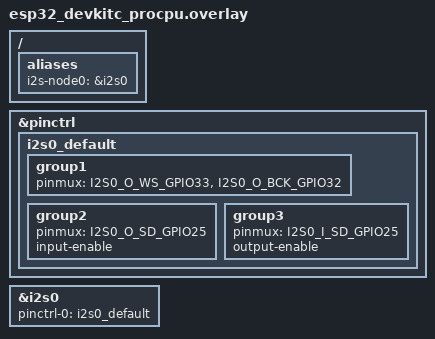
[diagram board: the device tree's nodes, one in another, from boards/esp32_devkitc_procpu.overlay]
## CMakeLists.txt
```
# SPDX-License-Identifier: Apache-2.0

cmake_minimum_required(VERSION 3.28.0)

find_package(Zephyr REQUIRED HINTS $ENV{ZEPHYR_BASE})
project(i2s_test)

FILE(GLOB app_sources src/*.c)
list(FILTER app_sources EXCLUDE REGEX "test_i2s_pm\\.c$")
target_sources(app PRIVATE ${app_sources})
target_sources_ifdef(CONFIG_PM app PRIVATE src/test_i2s_pm.c)
```

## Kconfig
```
#
# Copyright (c) 2025 Espressif Systems (Shanghai) CO LTD
#
# SPDX-License-Identifier: Apache-2.0
#

mainmenu "ESP32 I2S Loopback Test"

source "Kconfig.zephyr"

config I2S_TEST_SEPARATE_DEVICES
	bool "Use two separate I2S ports for loopback"
	help
	  Use separate I2S ports for transmit and receive.

config I2S_TEST_USE_GPIO_LOOPBACK
	bool "Use GPIO loopback"
	help
	  Use wiring between the data-out and data-in pins for looping back data.

config I2S_TEST_ALLOWED_DATA_DISCARD
	int "Allowed discard in received data"
	default 0
	help
	  Drop the first received block and allow later blocks to start this many
	  samples away from the transmitted block boundary. The offset must stay
	  fixed for the rest of the stream.
```

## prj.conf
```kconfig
CONFIG_I2S=y
CONFIG_ZTEST=y
CONFIG_TEST_USERSPACE=y
```

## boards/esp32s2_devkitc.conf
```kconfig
# Copyright (c) 2025 Espressif Systems (Shanghai) Co., Ltd.
# SPDX-License-Identifier: Apache-2.0

CONFIG_I2S_TEST_USE_GPIO_LOOPBACK=y
CONFIG_I2S_TEST_ALLOWED_DATA_DISCARD=2
CONFIG_I2S_ESP32_ALLOWED_EMPTY_TX_QUEUE_DEFERRAL_TIME_MS=1
```

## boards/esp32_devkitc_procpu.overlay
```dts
/*
 * Copyright (c) 2025 Espressif Systems (Shanghai) Co., Ltd.
 *
 * SPDX-License-Identifier: Apache-2.0
 */

/* i2s-node0 is the transmitter/receiver */

/ {
	aliases {
		i2s-node0 = &i2s0;
	};
};

&pinctrl {
	i2s0_default: i2s0_default {
		group1 {
			pinmux = <I2S0_O_WS_GPIO33>,
				 <I2S0_O_BCK_GPIO32>;
		};

		group2 {
			pinmux = <I2S0_O_SD_GPIO25>;
			input-enable;
		};

		group3 {
			pinmux = <I2S0_I_SD_GPIO25>;
			output-enable;
		};
	};
};

&i2s0 {
	pinctrl-0 = <&i2s0_default>;
	pinctrl-names = "default";
};
```

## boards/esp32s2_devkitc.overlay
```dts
/*
 * Copyright (c) 2025 Espressif Systems (Shanghai) Co., Ltd.
 *
 * SPDX-License-Identifier: Apache-2.0
 */

/* i2s-node0 is the transmitter/receiver */

/ {
	aliases {
		i2s-node0 = &i2s0;
	};
};

&i2s0_default {
	group1 {
		pinmux = <I2S0_O_WS_GPIO5>,
			 <I2S0_O_BCK_GPIO6>;
	};

	group2 {
		pinmux = <I2S0_O_SD_GPIO18>;
		input-enable;
	};

	group3 {
		pinmux = <I2S0_I_SD_GPIO18>;
		output-enable;
	};
};

&i2s0 {

	interrupts = <I2S0_INTR_SOURCE IRQ_DEFAULT_PRIORITY 0>,
		     <I2S0_INTR_SOURCE IRQ_DEFAULT_PRIORITY 0>;
	interrupt-names = "rx", "tx";
	status = "okay";
};
```

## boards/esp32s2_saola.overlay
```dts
/*
 * Copyright (c) 2025 Espressif Systems (Shanghai) Co., Ltd.
 *
 * SPDX-License-Identifier: Apache-2.0
 */

/* i2s-node0 is the transmitter/receiver */

/ {
	aliases {
		i2s-node0 = &i2s0;
	};
};

&i2s0_default {
	group1 {
		pinmux = <I2S0_O_WS_GPIO5>,
			 <I2S0_O_BCK_GPIO6>;
	};

	group2 {
		pinmux =  <I2S0_O_SD_GPIO18>;
		input-enable;
	};

	group3 {
		pinmux = <I2S0_I_SD_GPIO18>;
		output-enable;
	};
};

&i2s0 {
	status = "okay";

	interrupts = <I2S0_INTR_SOURCE IRQ_DEFAULT_PRIORITY 0>,
		     <I2S0_INTR_SOURCE IRQ_DEFAULT_PRIORITY 0>;
	interrupt-names = "rx", "tx";
};
```

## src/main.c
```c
/*
 * Copyright (c) 2025 Espressif Systems (Shanghai) Co., Ltd.
 *
 * SPDX-License-Identifier: Apache-2.0
 */

#include <zephyr/kernel.h>
#include <zephyr/ztest.h>
#include <zephyr/device.h>
#include <zephyr/drivers/i2s.h>

#define SAMPLE_NO      32
#define TIMEOUT        2000
#define FRAME_CLK_FREQ 8000

#define NUM_RX_BLOCKS 4
#define NUM_TX_BLOCKS 4

#define VAL_L 11
#define VAL_R 22

#define TRANSFER_REPEAT_COUNT 100

#define I2S_DEV_NODE_RX DT_ALIAS(i2s_node0)
#ifdef CONFIG_I2S_TEST_SEPARATE_DEVICES
#define I2S_DEV_NODE_TX DT_ALIAS(i2s_node1)
#else
#define I2S_DEV_NODE_TX DT_ALIAS(i2s_node0)
#endif

ZTEST_DMEM const struct device *dev_i2s_rx = DEVICE_DT_GET_OR_NULL(I2S_DEV_NODE_RX);
ZTEST_DMEM const struct device *dev_i2s_tx = DEVICE_DT_GET_OR_NULL(I2S_DEV_NODE_TX);
ZTEST_DMEM const struct device *dev_i2s = DEVICE_DT_GET_OR_NULL(I2S_DEV_NODE_RX);

#define BLOCK_SIZE (2 * SAMPLE_NO * sizeof(int16_t))

K_MEM_SLAB_DEFINE(rx_mem_slab, BLOCK_SIZE, NUM_RX_BLOCKS, 32);
K_MEM_SLAB_DEFINE(tx_mem_slab, BLOCK_SIZE, NUM_TX_BLOCKS, 32);

void fill_buf(int16_t *tx_block, int16_t val_l, int16_t val_r)
{
	for (int16_t i = 0; i < SAMPLE_NO; i++) {
		tx_block[2 * i] = val_l + i;
		tx_block[2 * i + 1] = val_r + i;
	}
}

static ZTEST_DMEM int discard_blocks;
static ZTEST_DMEM int block_start = -1;

void verify_buf_new_stream(void)
{
	discard_blocks = (CONFIG_I2S_TEST_ALLOWED_DATA_DISCARD > 0) ? 1 : 0;
	block_start = -1;
}

int verify_buf(int16_t *rx_block, int16_t val_l, int16_t val_r)
{
	/* ESP32 and ESP32-S2 can corrupt the first block of a stream. */
	if (discard_blocks > 0) {
		discard_blocks--;
		return TC_PASS;
	}

	/* Use the first valid block to determine this stream's fixed offset. */
	if (block_start < 0) {
		int start = rx_block[0] - val_l;

		if (start < 0 || start >= SAMPLE_NO ||
		    MIN(start, SAMPLE_NO - start) > CONFIG_I2S_TEST_ALLOWED_DATA_DISCARD) {
			TC_PRINT("Error: block starts %d %d, more than %d samples off\n",
				 (int)rx_block[0], (int)rx_block[1],
				 CONFIG_I2S_TEST_ALLOWED_DATA_DISCARD);
			return -TC_FAIL;
		}

		block_start = start;
	}

	for (int i = 0; i < SAMPLE_NO; i++) {
		int n = (block_start + i) % SAMPLE_NO;

		if (rx_block[2 * i] != (int16_t)(val_l + n) ||
		    rx_block[2 * i + 1] != (int16_t)(val_r + n)) {
			TC_PRINT("Error: data mismatch at position %d, expected %d %d, "
				 "actual %d %d\n",
				 i, (int)(val_l + n), (int)(val_r + n), (int)rx_block[2 * i],
				 (int)rx_block[2 * i + 1]);
			return -TC_FAIL;
		}
	}

	return TC_PASS;
}

static int tx_block_write_slab(const struct device *i2s_dev, int16_t val_l, int16_t val_r, int err,
			       struct k_mem_slab *slab)
{
	char tx_block[BLOCK_SIZE];
	int ret;

	fill_buf((uint16_t *)tx_block, val_l, val_r);
	ret = i2s_buf_write(i2s_dev, tx_block, BLOCK_SIZE);
	if (ret != err) {
		TC_PRINT("Error: i2s_write failed expected %d, actual %d\n", err, ret);
		return -TC_FAIL;
	}

	return TC_PASS;
}

int tx_block_write(const struct device *i2s_dev, int16_t val_l, int16_t val_r, int err)
{
	return tx_block_write_slab(i2s_dev, val_l, val_r, err, &tx_mem_slab);
}

static int rx_block_read_slab(const struct device *i2s_dev, int16_t val_l, int16_t val_r,
			      struct k_mem_slab *slab)
{
	char rx_block[BLOCK_SIZE];
	size_t rx_size;
	int ret;

	ret = i2s_buf_read(i2s_dev, rx_block, &rx_size);
	if (ret < 0 || rx_size != BLOCK_SIZE) {
		TC_PRINT("Error: Read failed\n");
		return -TC_FAIL;
	}
	ret = verify_buf((uint16_t *)rx_block, val_l, val_r);
	if (ret < 0) {
		TC_PRINT("Error: Verify failed\n");
		return -TC_FAIL;
	}

	return TC_PASS;
}

int rx_block_read(const struct device *i2s_dev, int16_t val_l, int16_t val_r)
{
	return rx_block_read_slab(i2s_dev, val_l, val_r, &rx_mem_slab);
}

int configure_stream(const struct device *i2s_dev, enum i2s_dir dir)
{
	int ret;
	struct i2s_config i2s_cfg = {0};

	i2s_cfg.word_size = 16U;
	i2s_cfg.channels = 2U;
	i2s_cfg.format = I2S_FMT_DATA_FORMAT_I2S;
	i2s_cfg.frame_clk_freq = FRAME_CLK_FREQ;
	i2s_cfg.block_size = BLOCK_SIZE;
	i2s_cfg.timeout = TIMEOUT;

	if (dir == I2S_DIR_TX) {
		/* Configure the Transmit port as Controller */
		i2s_cfg.options = I2S_OPT_FRAME_CLK_CONTROLLER | I2S_OPT_BIT_CLK_CONTROLLER;
	} else if (dir == I2S_DIR_RX) {
		/* Configure the Receive port as Target */
		i2s_cfg.options = I2S_OPT_FRAME_CLK_TARGET | I2S_OPT_BIT_CLK_TARGET;
	} else { /* dir == I2S_DIR_BOTH */
		i2s_cfg.options = I2S_OPT_FRAME_CLK_CONTROLLER | I2S_OPT_BIT_CLK_CONTROLLER;
	}

	if (!IS_ENABLED(CONFIG_I2S_TEST_USE_GPIO_LOOPBACK)) {
		i2s_cfg.options |= I2S_OPT_LOOPBACK;
	}

	if (dir == I2S_DIR_TX || dir == I2S_DIR_BOTH) {
		i2s_cfg.mem_slab = &tx_mem_slab;
		ret = i2s_configure(i2s_dev, I2S_DIR_TX, &i2s_cfg);
		if (ret < 0) {
			TC_PRINT("Failed to configure I2S TX stream (%d)\n", ret);
			return -TC_FAIL;
		}
	}

	if (dir == I2S_DIR_RX || dir == I2S_DIR_BOTH) {
		i2s_cfg.mem_slab = &rx_mem_slab;
		ret = i2s_configure(i2s_dev, I2S_DIR_RX, &i2s_cfg);
		if (ret < 0) {
			TC_PRINT("Failed to configure I2S RX stream (%d)\n", ret);
			return -TC_FAIL;
		}
	}

	return TC_PASS;
}

static void *setup(void)
{
	k_thread_access_grant(k_current_get(), &rx_mem_slab, &tx_mem_slab);
	k_object_access_grant(dev_i2s_rx, k_current_get());
	k_object_access_grant(dev_i2s_tx, k_current_get());

	return NULL;
}

static void before(void *fixture)
{
	ARG_UNUSED(fixture);

	int ret;

	zassert_not_null(dev_i2s_rx, "RX device not found");
	zassert_true(device_is_ready(dev_i2s_rx), "device %s is not ready", dev_i2s_rx->name);

	zassert_not_null(dev_i2s_tx, "TX device not found");
	zassert_true(device_is_ready(dev_i2s_tx), "device %s is not ready", dev_i2s_tx->name);

	ret = configure_stream(dev_i2s_rx, I2S_DIR_RX);
	zassert_equal(ret, TC_PASS);

	ret = configure_stream(dev_i2s_tx, I2S_DIR_TX);
	zassert_equal(ret, TC_PASS);
}

/** @brief I2S transfer.
 *
 * - START trigger starts both the transmission and reception.
 * - sending / receiving a sequence of data returns success.
 * - DRAIN trigger empties the transmit queue and stops both streams.
 */
ZTEST_USER(i2s_loopback, test_i2s_transfer)
{
	int ret;

	/* Prefill TX queue */
	ret = tx_block_write(dev_i2s, VAL_L, VAL_R, 0);
	zassert_equal(ret, TC_PASS);

	verify_buf_new_stream();

	ret = i2s_trigger(dev_i2s, I2S_DIR_BOTH, I2S_TRIGGER_START);
	zassert_equal(ret, 0, "RX/TX START trigger failed\n");

	for (int i = 0; i < TRANSFER_REPEAT_COUNT; i++) {
		ret = tx_block_write(dev_i2s_tx, VAL_L, VAL_R, 0);
		zassert_equal(ret, TC_PASS);

		ret = rx_block_read(dev_i2s_rx, VAL_L, VAL_R);
		zassert_equal(ret, TC_PASS);
	}

	/* All data written, all but one data block read, flush TX queue
	 * and stop both streams.
	 */
	ret = i2s_trigger(dev_i2s, I2S_DIR_BOTH, I2S_TRIGGER_DRAIN);
	zassert_equal(ret, 0, "RX/TX DRAIN trigger failed");
}

ZTEST_SUITE(i2s_loopback, NULL, setup, before, NULL, NULL);
```

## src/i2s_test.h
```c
/*
 * SPDX-FileCopyrightText: Copyright (c) 2026 Espressif Systems (Shanghai) CO LTD
 * SPDX-License-Identifier: Apache-2.0
 */

#ifndef I2S_TEST_H_
#define I2S_TEST_H_

#include <zephyr/device.h>
#include <zephyr/drivers/i2s.h>
#include <zephyr/kernel.h>

#define VAL_L 11
#define VAL_R 22

extern const struct device *dev_i2s_rx;
extern const struct device *dev_i2s_tx;
extern const struct device *dev_i2s;

extern struct k_mem_slab rx_mem_slab;
extern struct k_mem_slab tx_mem_slab;

int configure_stream(const struct device *i2s_dev, enum i2s_dir dir);
int tx_block_write(const struct device *i2s_dev, int16_t val_l, int16_t val_r, int err);
int rx_block_read(const struct device *i2s_dev, int16_t val_l, int16_t val_r);
void verify_buf_new_stream(void);
void i2s_test_recover(const struct device *dev);

#endif /* I2S_TEST_H_ */
```

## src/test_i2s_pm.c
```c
/*
 * SPDX-FileCopyrightText: Copyright (c) 2026 Espressif Systems (Shanghai) CO LTD
 * SPDX-License-Identifier: Apache-2.0
 */

#include <zephyr/kernel.h>
#include <zephyr/ztest.h>
#include <zephyr/drivers/i2s.h>
#include <zephyr/pm/pm.h>
#if defined(CONFIG_SOC_ESP32_PM_SLEEP_STATS)
#include <pmstats.h>
#endif
#include "i2s_test.h"

/* Drop the first block and verify the next two. */
#define TRANSFER_BLOCK_COUNT 3

static atomic_t standby_entries;

static void pm_state_entry(enum pm_state state)
{
	if (state == PM_STATE_STANDBY) {
		atomic_inc(&standby_entries);
	}
}

static struct pm_notifier pm_light_sleep_notifier = {
	.state_entry = pm_state_entry,
};

/* Stay idle and check that the chip really entered light sleep. */
static void check_light_sleep(void)
{
#if defined(CONFIG_SOC_ESP32_PM_SLEEP_STATS)
	struct esp32_sleep_window win;
	uint32_t seq = esp32_sleep_stats_get(NULL);
#endif

	atomic_clear(&standby_entries);
	k_sleep(K_MSEC(100));
	zassert_true(atomic_get(&standby_entries) > 0,
		     "System stayed active during the idle window");

#if defined(CONFIG_SOC_ESP32_PM_SLEEP_STATS)
	zassert_not_equal(esp32_sleep_stats_get(&win), seq,
			  "No light sleep window completed");
	zassert_true(win.slept > 0, "Light sleep was entered but nothing actually slept");
	zassert_equal(win.err, 0, "Light sleep failed with HAL error 0x%x",
		      (unsigned int)win.err);
#endif
}

static int run_i2s_loopback_once(void)
{
	int ret;

	/* Drop RX blocks left queued by the previous DRAIN. */
	i2s_test_recover(dev_i2s);

	ret = tx_block_write(dev_i2s, VAL_L, VAL_R, 0);
	if (ret != TC_PASS) {
		return ret;
	}

	verify_buf_new_stream();

	ret = i2s_trigger(dev_i2s, I2S_DIR_BOTH, I2S_TRIGGER_START);
	zassert_equal(ret, 0, "RX/TX START failed");

	for (int i = 0; i < TRANSFER_BLOCK_COUNT; i++) {
		ret = tx_block_write(dev_i2s_tx, VAL_L, VAL_R, 0);
		if (ret != TC_PASS) {
			return ret;
		}

		ret = rx_block_read(dev_i2s_rx, VAL_L, VAL_R);
		if (ret != TC_PASS) {
			return ret;
		}
	}

	/* All data written, all but one data block read, flush TX queue
	 * and stop both streams.
	 */
	ret = i2s_trigger(dev_i2s, I2S_DIR_BOTH, I2S_TRIGGER_DRAIN);
	zassert_equal(ret, 0, "RX/TX DRAIN failed");

	return TC_PASS;
}

static void *pm_setup(void)
{
	k_thread_access_grant(k_current_get(), &rx_mem_slab, &tx_mem_slab);
	k_object_access_grant(dev_i2s_rx, k_current_get());
	k_object_access_grant(dev_i2s_tx, k_current_get());

	return NULL;
}

static void pm_before(void *fixture)
{
	ARG_UNUSED(fixture);

	zassert_not_null(dev_i2s_rx, "RX device not found");
	zassert_true(device_is_ready(dev_i2s_rx), "device %s is not ready",
		     dev_i2s_rx->name);

	zassert_not_null(dev_i2s_tx, "TX device not found");
	zassert_true(device_is_ready(dev_i2s_tx), "device %s is not ready",
		     dev_i2s_tx->name);

	i2s_test_recover(dev_i2s);
}

/*
 * Configure once, then check that transfers still work after each light
 * sleep without configuring the stream again.
 */
ZTEST(i2s_pm, test_i2s_pm_light_sleep)
{
	int ret;

	ret = configure_stream(dev_i2s_rx, I2S_DIR_RX);
	zassert_equal(ret, TC_PASS);

	ret = configure_stream(dev_i2s_tx, I2S_DIR_TX);
	zassert_equal(ret, TC_PASS);

	pm_notifier_register(&pm_light_sleep_notifier);

	for (int cycle = 0; cycle < 2; cycle++) {
		check_light_sleep();
		zassert_equal(run_i2s_loopback_once(), TC_PASS);
	}

	pm_notifier_unregister(&pm_light_sleep_notifier);
}

ZTEST_SUITE(i2s_pm, NULL, pm_setup, pm_before, NULL, NULL);
```
